# QSPI register map
Vendor: Texas Instruments
Peripheral module from a debugger description file (folder am437x).
Registers are 32-bit, access not given, no defined reset value unless marked. A register's access mark holds for its fields unless they carry their own. Offsets are as the file gives them; lines under a group give offsets from that group; [hi:lo] are bit positions; {n}, {i} and the like mark numbered series; 'fields as' and 'values as' point back to an identical list; <NAME> marks a mode.

## QSPI
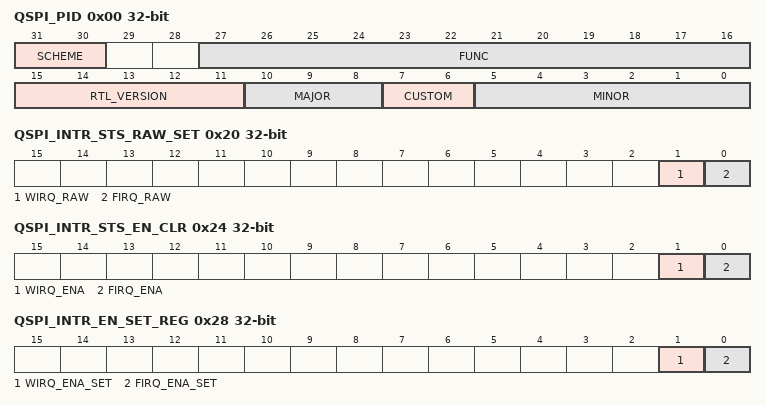
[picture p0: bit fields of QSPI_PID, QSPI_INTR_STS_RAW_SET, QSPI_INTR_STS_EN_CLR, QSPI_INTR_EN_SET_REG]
0x00 QSPI_PID ro
  [31:30] SCHEME — The scheme of the register used. [[br]]This indicates the PDR3.5 Method
  [27:16] FUNC — The function of the module being used
  [15:11] RTL_VERSION — RTL version number
  [10:8] MAJOR — Major revision number
  [7:6] CUSTOM
  [5:0] MINOR — Minor Revision Number
0x10 QSPI_SYSCONFIG access per field
  [3:2] IDLE_MODE rw — Configuration of the local target state management mode. [[br]]By definition, target can handle read/write transaction as long as it is out of IDLE state
    3=en_4_0x3 (Smart-idle wakeup-capable mode: local target's idle state eventually follows (acknowledges) the system's idle requests, depending on the IP module's internal requirements. IP module may generate (IRQ- or DMA-request-related) wakeup events when in idle state. Mode is only relevant if the appropriate IP module "swakeup" output(s) is (are) implemented); 2=en_3_0x2 (Smart-idle mode: local target's idle state eventually follows (acknowledges) the system's idle requests, depending on the IP module's internal requirements. IP module shall not generate (IRQ- or DMA-request-related) wakeup events); 1=en_2_0x1 (No-idle mode: local target never enters idle state.); 0=en_1_0x0 (Local target's idle state follows (acknowledges) the system's idle requests unconditionally, i.e. regardless of the IP module's internal requirements.)
0x20 QSPI_INTR_STS_RAW_SET rw — This register contains the raw interrupt status.
  [1] WIRQ_RAW — Word Interrupt Status. [[br]]Read indicates raw status. [[br]]Writing 1 will set status. [[br]]Writing 0 has no effect. [[br]]
    1=en_2_0x1 (Active.); 0=en_1_0x0 (Inactive.)
  [0] FIRQ_RAW — Frame Interrupt Status. [[br]]Read indicates raw status. [[br]]Writing 1 will set status. [[br]]Writing 0 has no effect. [[br]]
    1=en_2_0x1 (Active.); 0=en_1_0x0 (Inactive.)
0x24 QSPI_INTR_STS_EN_CLR access per field — Interrupt Status Enabled/Clear Register.
  [1] WIRQ_ENA rw — Word Interrupt Enabled Status. [[br]]Read indicates enabled status. [[br]]Writing 1 will clear interrupt. [[br]]Writing 0 has no effect. [[br]]
    1=en_2_0x1 (Active.); 0=en_1_0x0 (Inactive.)
  [0] FIRQ_ENA rw — Frame Interrupt Enabled Status. [[br]]Read indicates enabled status. [[br]]Writing 1 will clear interrupt. [[br]]Writing 0 has no effect. [[br]]
    1=en_2_0x1 (Active.); 0=en_1_0x0 (Inactive.)
0x28 QSPI_INTR_EN_SET_REG access per field — Interrupt Enable/Set Register.
  [1] WIRQ_ENA_SET rw — Word Interrupt Enable/Set. [[br]]Read indicates interrupt enable. [[br]]Writing 1 will set interrupt enabled. [[br]]Writing 0 has no effect. [[br]]
    1=en_2_0x1 (Active.); 0=en_1_0x0 (Inactive.)
  [0] FIRQ_ENA_SET rw — Frame Interrupt Enable/Set. [[br]]Read indicates interrupt enable. [[br]]Writing 1 will set interrupt enabled. [[br]]Writing 0 has no effect. [[br]]
    1=en_2_0x1 (Active.); 0=en_1_0x0 (Inactive.)
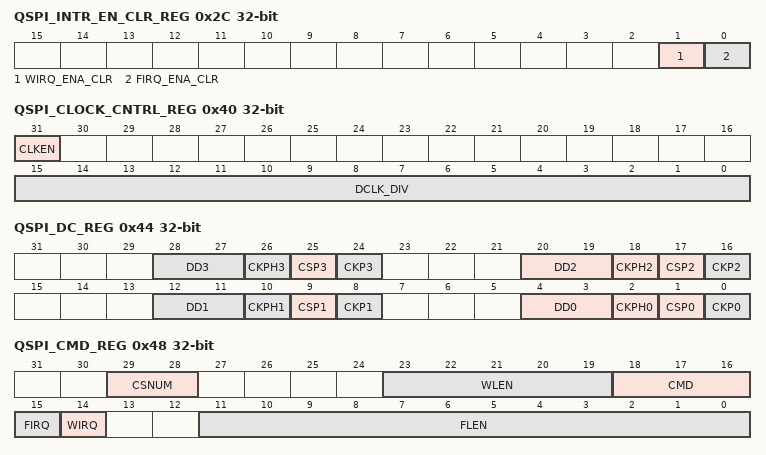
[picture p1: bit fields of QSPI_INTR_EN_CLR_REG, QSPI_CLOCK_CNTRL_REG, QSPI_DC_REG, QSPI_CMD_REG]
0x2C QSPI_INTR_EN_CLR_REG access per field — Interrupt Enable/Clear Register.
  [1] WIRQ_ENA_CLR rw — Word Interrupt Enable/Clear. [[br]]Read indicates interrupt enable. [[br]]Writing 1 will clear interrupt enabled. [[br]]Writing 0 has no effect. [[br]]
    1=en_2_0x1 (Active.); 0=en_1_0x0 (Inactive.)
  [0] FIRQ_ENA_CLR rw — Frame Interrupt Enable/Clear. [[br]]Read indicates interrupt enable. [[br]]Writing 1 will clear interrupt enabled. [[br]]Writing 0 has no effect. [[br]]
    1=en_2_0x1 (Active.); 0=en_1_0x0 (Inactive.)
0x40 QSPI_CLOCK_CNTRL_REG access per field — SPI Clock Control (SPICC) Register. SPICC controls the SPI clock generation. The SPICC controls the SPI clock generation. The input for clock division is the input SPI_CLK signal. The output clock will be divided by DCLK_DIV+1 to provide the output SPI interface clock as well as controlling the main portion of the design. Note that loading a value or 0 input DCLK_DIV will force the input SPI_CLK to be used directly for the SPI interface clock. The value in DCLK_DIV is only loaded when CLKEN transitions from a 0 to 1 state. This register can only be written to when the SPI is not busy, as defined by SPISR[0].
  [31] CLKEN rw — Clock Enable.
    1=en_2_0x1 (Data clock is enabled.); 0=en_1_0x0 (Data clock is turned off.)
  [15:0] DCLK_DIV rw — Serial data clock divide by ratio
0x44 QSPI_DC_REG — SPI Device Control (SPIDC) Register. The SPIDC controls the different modes for each output chip select. The SPIDC controls the different modes for each output chip select. NOTE: The combination of [CKPn, CKPHn] creates the SPI mode . Most serial Flash devices only support SPI modes 0 and 3. SPI devices transmit and receive data on opposite edge s of the SPI clock. Note that changing the clock polarity also swaps the transmit/receive clock edge relationship. If a slave device states that it receives data on the rising edge and transmits on the falling edge of the clock, then it can only support mode 0 or 3 (CKPn = 0, CKPHn = 0 OR CKPn = 1, CKPHn = 1). This register can only be written to when the SPI is not busy, as defined by SPISR[0].
  [8n+4:8n+3] DD{n} (n=0..3) — Data delay for chip select {n}. [[br]]
    3=en_4_0x3 (Data is output 3 DCLK cycles after the CS_N goes active.); 2=en_3_0x2 (Data is output 2 DCLK cycles after the CS_N goes active.); 1=en_2_0x1 (Data is output 1 DCLK cycle after the CS_N goes active.); 0=en_1_0x0 (Data is output on the same cycle as the CS_N goes active.)
  [8n+2] CKPH{n} (n=0..3) — Clock phase for chip select {n}. [[br]]See register description note. [[br]]
    1=en_2_0x1 (If CKP{n} = 0, data shifted out on rising edge and input on falling edge. If CKP{n} = 1, data shifted out on falling edge and input on rising edge.); 0=en_1_0x0 (If CKP{n} = 0, data shifted out on falling edge and input on rising edge. If CKP{n} = 1, data shifted out on rising edge and input on falling edge.)
  [25] CSP3 — Chip select polarity for chip select 3. [[br]]
    1=en_2_0x1 (Active high.); 0=en_1_0x0 (Active low.)
  [24] CKP3 — Clock polarity for chip select 3. [[br]]
    1=en_2_0x1 (When data is being transferred, SCK = 1); 0=en_1_0x0 (When data is not being transferred, SCK = 0)
  [17] CSP2 — Chip select polarity for chip select 2. [[br]]
    1=en_2_0x1 (Active high.); 0=en_1_0x0 (Active low.)
  [16] CKP2 — Clock polarity for chip select 2. [[br]]
    values as CKP3
  [9] CSP1 — Chip select polarity for chip select 1. [[br]]
    1=en_2_0x1 (Active high.); 0=en_1_0x0 (Active low.)
  [8] CKP1 — Clock polarity for chip select 1. [[br]]
    values as CKP3
  [1] CSP0 — Chip select polarity for chip select. [[br]]
    1=en_2_0x1 (Active high.); 0=en_1_0x0 (Active low.)
  [0] CKP0 — Clock polarity for chip select. [[br]]
    values as CKP3
0x48 QSPI_CMD_REG access per field — SPI Command Register (SPICR). Sets up the SPI command. Since the SPI convention is to always shift in new data (LSB position) while shifting out data from the MSB position the 'read', 'write' and 'read dual' commands actually just initiate a transfer. Write commands will assert the spi_dout_oe_n signal to enable the tristate buffer for spi_dout_o. Read commands will deassert the spi_dout_oe_n signal to disable the tristate buffer for spi_dout_o. Executing any of these commands will initiate the next word transfer (except for the case of "read dual"). The 'read dual' command will also initiate a transfer like read or write. However, this command is used to communicate with serial Flash devices which support dual read output. Dual read output mode uses the spi_dout signal as an input along with the spi_din input (spi_dout is therefore a bidirectional signal). WLEN transfers must be even. The spi_din input will contain the odd number bytes and the spi_dout bidirectional/input will contain the even number bytes. This read mode effectively doubles the read bandwidth of the design. This command can only be used on those devices which support a dual read command. The 'read quad' command is similar to the read dual command, except it uses a 6 pin interface. The In particular, transfers are started by writing to byte 2 of this register (only byte 2 will start a transfer). Writing a "reserved" value to the CMD register will terminate the frame transfer. This can be used to abort a frame if desired. Reserved commands are CMD = 00 and CMD_MODE=1 AND CMD=11. This register can only be written to when the SPI is not busy, as defined by SPISR[0]. If the SPI clock has not been enabled (SPICC[31] = 0), then writing to this register will NOT start the SPI transfer. The transfer will not be queued to start upon the activation of the clock. The transfer will ONLY start if SPICC[31] = 1 when this register is written.
  [29:28] CSNUM rw — Device select. [[br]]Sets the active chip select for the transfer. [[br]]
    3=en_4_0x3 (Reserved.); 2=en_3_0x2 (Reserved.); 1=en_2_0x1 (Reserved.); 0=en_1_0x0 (Chip select 0 active.)
  [23:19] WLEN rw — Word length. [[br]]Sets the size of the individual transfers from 1 to 32 bits.
    31=en_3_0x1F (32 bits.); 1=en_2_0x1 (2 bits.); 0=en_1_0x0 (1 bit.)
  [18:16] CMD rw — Transfer command. [[br]]
    7=en_6_0x7 (6 pin Read Quad); 6=en_5_0x6 (3 pin Write Single); 5=en_4_0x5 (3 pin Read Single); 3=en_3_0x3 (4 pin Read Dual); 2=en_2_0x2 (4 pin Write Single); 1=en_1_0x1 (4 pin Read Single)
  [15] FIRQ rw — Frame count interrupt enable.
    1=en_2_0x1 (Enable.); 0=en_1_0x0 (Disable.)
  [14] WIRQ rw — Word count interrupt enable.
    1=en_2_0x1 (Enable.); 0=en_1_0x0 (Disable.)
  [11:0] FLEN rw — Frame Length.
    0xFFF=en_3_0xFFF (4096 words.); 1=en_2_0x1 (2 words.); 0=en_1_0x0 (1 word.)
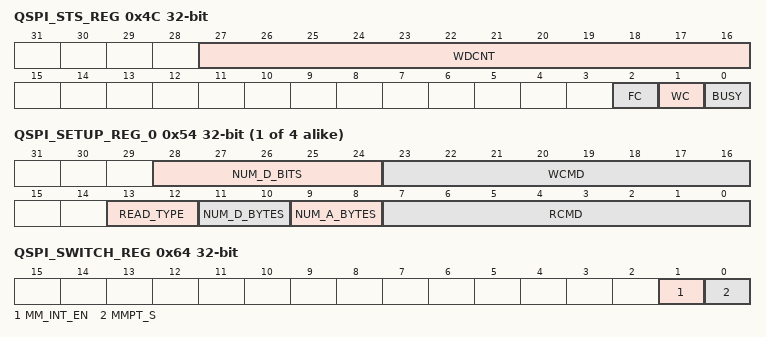
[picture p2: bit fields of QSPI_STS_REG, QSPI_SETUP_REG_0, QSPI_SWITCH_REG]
0x4C QSPI_STS_REG access per field — SPI Status Register (SPISR). The SPI Status Register contains indicators to allow the user to monitor the progression of a frame transfer. The SPI Status Register contains indicators to allow the user to monitor the progression of a frame transfer. The word complete (WC) and frame complete (FC) bits are used as stimulus for generating interrupts. Setting the corresponding interrupt enable bit in the SPI Command Register will allow these events to generate an interrupt. The WDCNT field will reset itself when transitioning from the LOAD state to the SHIFT state. THE WC and FC fields will be reset every time the user writes to the SPI Command Register or the SPI Status Register is read. The BUSY bit of this register (SPISR[0]) is used to block write access to the SPICC, SPIDC, SPICR and SPIDR registers. This is done to keep control parameters from changing the interface protocol signals while a transfer is in progress. If a write is made while BUSY is active, the write will simply not occur. BUSY is set immediately when SPICR[18:16] are written and BUSY will be cleared when the current word has completed transfer (on SPISR[1]). However, if the SPI clock enable is not set (SPICC[31] = 0) and a command is executed (SPICR[18:16] is written to start a command), BUSY will NOT be set and the command will not be executed. BUSY will ONLY go high if SPICC[31] = 1 and SPICR[18:16] is written.
  [27:16] WDCNT rw — Word count. [[br]]This field will reflect the 1 to 4096 words transferred
  [2] FC rw — Frame complete. [[br]]This bit is set after all of the requested words have been transmitted.
    1=en_2_0x1 (Transfer is complete. This bit is reset when the SPI Status Register is read.); 0=en_1_0x0 (Transfer is not complete.)
  [1] WC rw — Word complete. [[br]]This bit is set after each word transfer is completed.
    1=en_2_0x1 (Word transfer is complete. This bit is reset when the SPI Status Register is read.); 0=en_1_0x0 (Word transfer is not complete.)
  [0] BUSY rw — Busy bit. [[br]]Active transfer in progress. [[br]]This bit is only set during an active word transfer. [[br]]Between words, the bit will clear to signal that it is ok to read/write the data registers.
    1=en_2_0x1 (Busy.); 0=en_1_0x0 (Idle.)
0x50 QSPI_DATA_REG — SPI Data Register (SPIDR). Data received in the data register is shifted into the LSB position and the contents of the register are shifted to the left. The register is cleared between reads or writes. Data received in the data register is shifted into the LSB position and the contents of the register are shifted to the left. The register is cleared between reads or writes. When writing data to the register it should be right justified so pre-shifting is not required. The word length field will determine the location of the most significant bit and the bit position that will be shifted out first during a write. In order to shift out byte data the word length should be set to 7 and the data byte should be written to the lower byte of the data register. By setting the word length to 7 the data register will look like a pseudo 8-bit shift register. The word length setting does not affect the VBUSP read or write operations. This register can only be written to when the SPI is not busy, as defined by SPISR[0].
  [31:0] DATA — Data register for read and write operations
{0x54+4i} QSPI_SETUP_REG_{i} (i=0..3) — Memory Mapped SPI Setup Register n. The Memory Mapped SPI Setup Register contains the read/write command setup for the Memory Mapped Protocol Translator (effecting Chip Select n output). The Memory Mapped SPI Setup Register contains the read/write command setup for the Memory Mapped Protocol Translator, request n input (effecting Chip Select n output). This corresponds to MAddrSpace = 001 (n = 0), MAddrSpace = 010 (n = 1), MAddrSpace = 011 (n = 2), and MAddrSpace = 100, 101, 110, and 111 (n = 3) . Note that by default (reset), the device uses a write command of 2, read command of 3 and number of address bytes of 3. This default covers most serial Flash devices, but can be changed.
  [28:24] NUM_D_BITS — Number of dummy bits to use if NUM_D_BYTES = 0.
  [23:16] WCMD — Write command.
  [13:12] READ_TYPE — Determines if the read command is a single, dual or quad read mode command.
    3=en_4_0x3 (Quad read (uses spi_qdin0/1)); 2=en_3_0x2 (Normal read (all data input on spi_din)); 1=en_2_0x1 (Dual read (odd bytes input on spi_din; even on spi_dout)); 0=en_1_0x0 (Normal read (all data input on spi_din))
  [11:10] NUM_D_BYTES — Number of dummy bytes to be used for fast read.
    3=en_4_0x3 (3); 2=en_3_0x2 (2); 1=en_2_0x1 (1); 0=en_1_0x0 (No dummy bytes required.)
  [9:8] NUM_A_BYTES — Number of address bytes to be sent.
    3=en_4_0x3 (4 bytes.); 2=en_3_0x2 (3 bytes.); 1=en_2_0x1 (2 bytes.); 0=en_1_0x0 (1 byte.)
  [7:0] RCMD — Read Command.
0x64 QSPI_SWITCH_REG access per field — Memory Mapped SPI Switch Register. The Memory Mapped SPI Switch Register allows the CPU to switch control of the core SPI module's configuration port between the configuration VBUSP port and the Memory Mapped Protocol Translator. The Memory Mapped SPI Switch Register allows the CPU to switch control of the core SPI module s configuration port between the configuration VBUSP port and the Memory Mapped Protocol Translator. In addition, an interrupt enable field is defined which is used to enable or disable word count interrupt generation in memory mapped mode.
  [1] MM_INT_EN rw — Memory Mapped mode interrupt enable. [[br]]
    1=en_2_0x1 (Word count interrupts are enabled for memory mapped operations.); 0=en_1_0x0 (Interrupts are disabled during memory mapped operations.)
  [0] MMPT_S rw — MMPT select.
    1=en_2_0x1 (Memory mapped protocol translator is selected to control configuration port of core SPI module.); 0=en_1_0x0 (Configuration port is selected to control configuration of core SPI module.)
{0x64+4i} QSPI_DATA_REG_{i} (i=1..3) — SPI Data{i} Register (SPIDR{i}). Data received in the data register is shifted into the LSB position and the contents of the register are shifted to the left. The register is cleared between reads or writes. This acts as the 2nd 32 bit register of the 128 bit shift register in/out Data received in the data register is shifted into the LSB position and the contents of the register are shifted to the left. The register is cleared between reads or writes. When writing data to the register it should be right justified so pre-shifting is not required. The word length field will determine the location of the most significant bit and the bit position that will be shifted out first during a write. In order to shift out byte data the word length should be set to '7' and the data byte should be written to the lower byte of the data register. By setting the word length to '7' the data register will look like a pseudo 8-bit shift register. The word length setting does not affect the VBUSP read or write operations.
  [31:0] DATA — Data register for read and write operations
